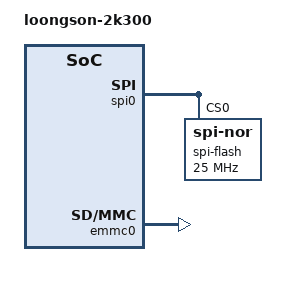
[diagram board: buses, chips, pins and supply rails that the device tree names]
#include "ls2k300.dtsi"

/ {
	model = "loongson-2k300";

	chosen {
		stdout-path = "serial0:115200n8";
		bootargs = "earlycon";
	};

	reserved-memory {
		#address-cells = <2>;
		#size-cells = <2>;
		ranges;

		bootparam: bootparam_region {
			reg = <0x90000000 0x0f000000 0x0 0x1000000>;
			no-map;
		};
	};
};

&spi0 {
	status = "okay";

	spi-flash@0 {
		compatible = "jedec,spi-nor";
		spi-max-frequency = <25000000>; /* input clock */
		reg = <0>; /* CS0 */
	};
};

&emmc0 {
	status = "okay";
};

